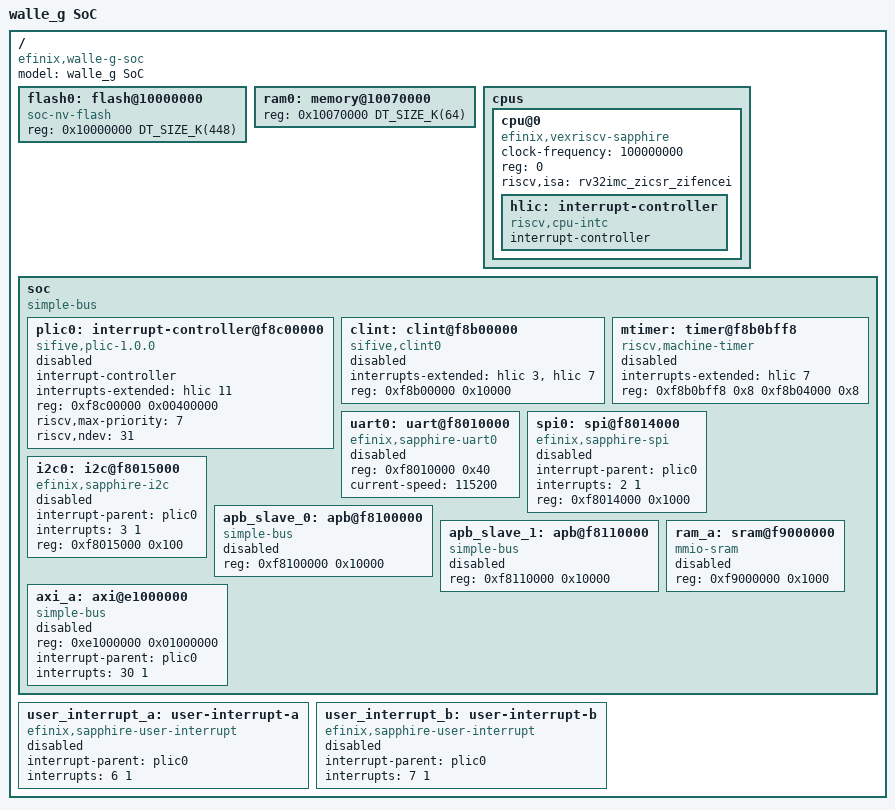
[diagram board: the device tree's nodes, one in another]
/*
 * Copyright (c) 2024
 *
 * SPDX-License-Identifier: Apache-2.0
 */

#include <mem.h>

/ {
	#address-cells = <1>;
	#size-cells = <1>;
	model = "walle_g SoC";
	compatible = "efinix,walle-g-soc", "efinix,sapphire";

	/*
	 * Keep ram_code as the ROM/XIP region and ram_main as data SRAM.
	 * This matches walle_sram.ld:
	 *   ram_code: 0x10000000, size 0x70000
	 *   ram_main: 0x10070000, size 0x10000
	 */
	flash0: flash@10000000 {
		compatible = "soc-nv-flash";
		reg = <0x10000000 DT_SIZE_K(448)>;
	};

	ram0: memory@10070000 {
		device_type = "memory";
		reg = <0x10070000 DT_SIZE_K(64)>;
	};

	cpus {
		#address-cells = <1>;
		#size-cells = <0>;

		cpu@0 {
			clock-frequency = <100000000>;
			compatible = "efinix,vexriscv-sapphire", "riscv";
			device_type = "cpu";
			reg = <0>;
			riscv,isa = "rv32imc_zicsr_zifencei";
			status = "okay";

			hlic: interrupt-controller {
				compatible = "riscv,cpu-intc";
				#address-cells = <0>;
				#interrupt-cells = <1>;
				interrupt-controller;
			};
		};
	};

	soc {
		#address-cells = <1>;
		#size-cells = <1>;
		compatible = "simple-bus";
		ranges;

		plic0: interrupt-controller@f8c00000 {
			compatible = "sifive,plic-1.0.0";
			#address-cells = <0>;
			#interrupt-cells = <2>;
			interrupt-controller;
			interrupts-extended = <&hlic 11>;
			reg = <0xf8c00000 0x00400000>;
			riscv,max-priority = <7>;
			riscv,ndev = <31>;
			status = "disabled";
		};

		clint: clint@f8b00000 {
			compatible = "sifive,clint0";
			interrupts-extended = <&hlic 3 &hlic 7>;
			reg = <0xf8b00000 0x10000>;
			status = "disabled";
		};

		mtimer: timer@f8b0bff8 {
			compatible = "riscv,machine-timer";
			interrupts-extended = <&hlic 7>;
			reg = <0xf8b0bff8 0x8 0xf8b04000 0x8>;
			reg-names = "mtime", "mtimecmp";
			status = "disabled";
		};

		uart0: uart@f8010000 {
			compatible = "efinix,sapphire-uart0";
			reg = <0xf8010000 0x40>;
			reg-names = "base";
			current-speed = <115200>;
			status = "disabled";
		};

		spi0: spi@f8014000 {
			compatible = "efinix,sapphire-spi";
			interrupt-parent = <&plic0>;
			interrupts = <2 1>;
			reg = <0xf8014000 0x1000>;
			#address-cells = <1>;
			#size-cells = <0>;
			status = "disabled";
		};

		i2c0: i2c@f8015000 {
			compatible = "efinix,sapphire-i2c";
			interrupt-parent = <&plic0>;
			interrupts = <3 1>;
			reg = <0xf8015000 0x100>;
			#address-cells = <1>;
			#size-cells = <0>;
			status = "disabled";
		};

		apb_slave_0: apb@f8100000 {
			compatible = "simple-bus";
			reg = <0xf8100000 0x10000>;
			ranges;
			#address-cells = <1>;
			#size-cells = <1>;
			status = "disabled";
		};

		apb_slave_1: apb@f8110000 {
			compatible = "simple-bus";
			reg = <0xf8110000 0x10000>;
			ranges;
			#address-cells = <1>;
			#size-cells = <1>;
			status = "disabled";
		};

		ram_a: sram@f9000000 {
			compatible = "mmio-sram";
			reg = <0xf9000000 0x1000>;
			status = "disabled";
		};

		axi_a: axi@e1000000 {
			compatible = "simple-bus";
			reg = <0xe1000000 0x01000000>;
			ranges;
			#address-cells = <1>;
			#size-cells = <1>;
			interrupt-parent = <&plic0>;
			interrupts = <30 1>;
			status = "disabled";
		};
	};

	user_interrupt_a: user-interrupt-a {
		compatible = "efinix,sapphire-user-interrupt";
		interrupt-parent = <&plic0>;
		interrupts = <6 1>;
		status = "disabled";
	};

	user_interrupt_b: user-interrupt-b {
		compatible = "efinix,sapphire-user-interrupt";
		interrupt-parent = <&plic0>;
		interrupts = <7 1>;
		status = "disabled";
	};
};
